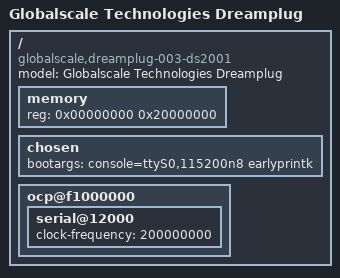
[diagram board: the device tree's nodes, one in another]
/*
 * arch/arm/boot/dts/kirkwood-dreamplug.dts
 *
 * Copyright (C) 2012-2014 NVIDIA Corporation. All rights reserved.
 *
 * This software is licensed under the terms of the GNU General Public
 * License version 2, as published by the Free Software Foundation, and
 * may be copied, distributed, and modified under those terms.
 *
 * This program is distributed in the hope that it will be useful,
 * but WITHOUT ANY WARRANTY; without even the implied warranty of
 * MERCHANTABILITY or FITNESS FOR A PARTICULAR PURPOSE.  See the
 * GNU General Public License for more details.
 *
 */

/dts-v1/;

/include/ "kirkwood.dtsi"

/ {
	model = "Globalscale Technologies Dreamplug";
	compatible = "globalscale,dreamplug-003-ds2001", "globalscale,dreamplug", "mrvl,kirkwood-88f6281", "mrvl,kirkwood";

	memory {
		device_type = "memory";
		reg = <0x00000000 0x20000000>;
	};

	chosen {
		bootargs = "console=ttyS0,115200n8 earlyprintk";
	};

	ocp@f1000000 {
		serial@12000 {
			clock-frequency = <200000000>;
			status = "ok";
		};
	};
};
